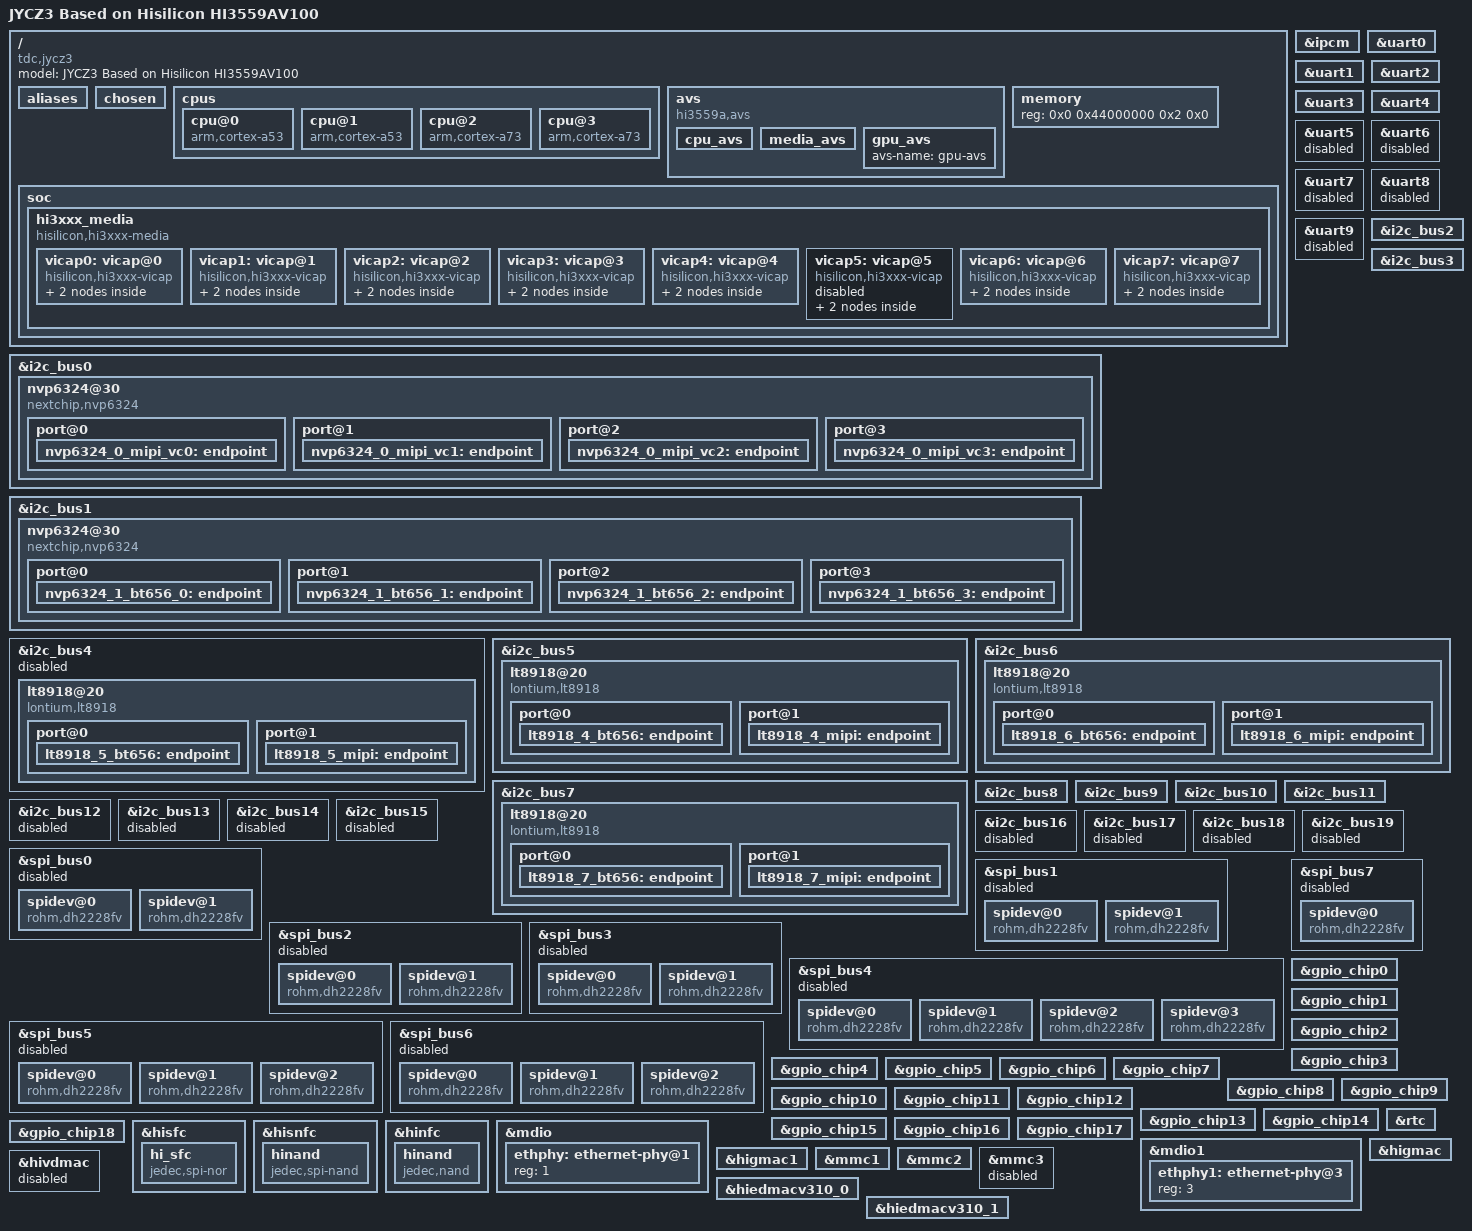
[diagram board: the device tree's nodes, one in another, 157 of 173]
/* Copyright (c) 2017 HiSilicon Technologies Co., Ltd.
 *
 * This program is free software; you can redistribute  it and/or modify it
 * under  the terms of  the GNU General  Public License as published by the
 * Free Software Foundation;  either version 2 of the  License, or (at your
 * option) any later version.
 *
 * This program is distributed in the hope that it will be useful,
 * but WITHOUT ANY WARRANTY; without even the implied warranty of
 * MERCHANTABILITY or FITNESS FOR A PARTICULAR PURPOSE. See the
 * GNU General Public License for more details.
 *
 * You should have received a copy of the GNU General Public License
 * along with this program.  If not, see <http://www.gnu.org/licenses/>.
 *
 */

/dts-v1/;
/* reserved for warmreset */
/* reserved for arm trustedfirmware */
/* Modify this configuration according to the system framework */
/memreserve/ 0x47000000 0x00200000;
#include "hi3559av100.dtsi"

/ {
	model = "JYCZ3 Based on Hisilicon HI3559AV100";
	compatible = "tdc,jycz3", "hisilicon,hi3559av100";

	aliases {
		serial0 = &uart0;
		serial1 = &uart1;
		serial2 = &uart2;
		serial3 = &uart3;
		serial4 = &uart4;
		serial5 = &uart5;
		serial6 = &uart6;
		serial7 = &uart7;
		serial8 = &uart8;
		serial9 = &uart9;

		i2c0 = &i2c_bus0;
		i2c1 = &i2c_bus1;
		i2c2 = &i2c_bus2;
		i2c3 = &i2c_bus3;
		i2c4 = &i2c_bus4;
		i2c5 = &i2c_bus5;
		i2c6 = &i2c_bus6;
		i2c7 = &i2c_bus7;
		i2c8 = &i2c_bus8;
		i2c9 = &i2c_bus9;
		i2c10 = &i2c_bus10;
		i2c11 = &i2c_bus11;
		i2c12 = &i2c_bus12;
		i2c13 = &i2c_bus13;
		i2c14 = &i2c_bus14;
		i2c15 = &i2c_bus15;
		i2c16 = &i2c_bus16;
		i2c17 = &i2c_bus17;
		i2c18 = &i2c_bus18;
		i2c19 = &i2c_bus19;

		spi0 = &spi_bus0;
		spi1 = &spi_bus1;
		spi2 = &spi_bus2;
		spi3 = &spi_bus3;
		spi4 = &spi_bus4;
		spi5 = &spi_bus5;
		spi6 = &spi_bus6;
		spi7 = &spi_bus7;

		gpio0 = &gpio_chip0;
		gpio1 = &gpio_chip1;
		gpio2 = &gpio_chip2;
		gpio3 = &gpio_chip3;
		gpio4 = &gpio_chip4;
		gpio5 = &gpio_chip5;
		gpio6 = &gpio_chip6;
		gpio7 = &gpio_chip7;
		gpio8 = &gpio_chip8;
		gpio9 = &gpio_chip9;
		gpio10 = &gpio_chip10;
		gpio11 = &gpio_chip11;
		gpio12 = &gpio_chip12;
		gpio13 = &gpio_chip13;
		gpio14 = &gpio_chip14;
		gpio15 = &gpio_chip15;
		gpio16 = &gpio_chip16;
		gpio17 = &gpio_chip17;
		gpio18 = &gpio_chip18;
		videv0 = &vicap0;
		videv1 = &vicap1;
		videv2 = &vicap2;
		videv3 = &vicap3;
		videv4 = &vicap4;
		videv5 = &vicap5;
		videv6 = &vicap6;
		videv7 = &vicap7;
	};

	chosen {
		bootargs = "mem=512M console=ttyAMA0,115200 clk_ignore_unused root=/dev/mtdblock2 rootfstype=yaffs2 rw mtdparts=hinand:1M(boot),9M(kernel),32M(rootfs),1M(this_bootargs_string_is_reserved_for_bootargs_form_uboot!!!_it_must_be_longer_than_bootargs_form_uboot!!!_this_bootargs_string_is_reserved_for_bootargs_form_uboot!!!_it_must_be_longer_than_bootargs_form_uboot!!!_this_bootargs_string_is_reserved_for_bootargs_form_uboot!!!_it_must_be_longer_than_bootargs_form_uboot!!!_this_bootargs_string_is_reserved_for_bootargs_form_uboot!!!_it_must_be_longer_than_bootargs_form_uboot!!!_this_bootargs_string_is_reserved_for_bootargs_form_uboot!!!_it_must_be_longer_than_bootargs_form_uboot!!!)";

		linux,initrd-start = <0x60000040>;
		linux,initrd-end = <0x61000000>;
	};

	cpus {
		#address-cells = <2>;
		#size-cells = <0>;

		cpu@0 {
			compatible = "arm,cortex-a53";
			device_type = "cpu";
			reg = <0x0 0x0>;
			enable-method = "psci";
			clock-latency = <100000>; /* From legacy driver */
			cpu-idle-states = <&CPU_POWERDOWN &CPU_STANDBY>;
		};

		cpu@1 {
			compatible = "arm,cortex-a53";
			device_type = "cpu";
			reg = <0x0 0x1>;
			enable-method = "psci";
			clock-latency = <200000>; /* From legacy driver */
			cpu-idle-states = <&CPU_POWERDOWN &CPU_STANDBY>;
		};
		cpu@2 {
			compatible = "arm,cortex-a73";
			device_type = "cpu";
			reg = <0x0 0x100>;
			enable-method = "psci";
			cpu-idle-states = <&CPU_POWERDOWN &CPU_STANDBY>;
			vcc-supply = <&a73_regulator>;
		};
		cpu@3 {
			compatible = "arm,cortex-a73";
			device_type = "cpu";
			reg = <0x0 0x101>;
			enable-method = "psci";
			operating-points = <
				792000 796000
				1296000 888000
				1608000 988000
				>;
			clocks = <&clock HI3559AV100_A73_MUX>,
					<&clock HI3559AV100_FIXED_24M>,
					<&clock HI3559AV100_APLL_CLK>,
					<&clock HI3559AV100_FIXED_1000M>;
			clock-names = "a73_mux","24m","apll","1000m";
			clock-latency = <400000>; /* From legacy driver */
			cpu-idle-states = <&CPU_POWERDOWN &CPU_STANDBY>;
			vcc-supply = <&a73_regulator>;
		};

	};

	avs {
	    compatible = "hi3559a,avs";
	    avs-num = <3>;
	    avs-name-array = "cpu-avs","media-avs","gpu-avs";
	    cpu_avs: cpu_avs{
			avs-name = "cpu-avs";
			opp-num = <6>;
			opp-freq = <1250000 1150000 1000000 930000 792000 594000 >;
			opp-volt-min = <870000 870000 800000 800000 740000 740000>;
			opp-hpm = <310 310 280 280 250 250>;
			opp-div = <24 22 19 18 15 11>;
			opp-volt-max = <1060000>;
			};

	    media_avs: media_avs{
			avs-name = "media-avs";
			opp-num = <4>;
			opp-prof-num = <2>;
			opp-temp-num = <2>;
			opp-temp = <50 200>;
			opp-freq = <1 2 3 4>;
			opp-volt-min = <
				/* profile2    profile3*/
                  770000       770000
                  770000       770000
				  >;
			opp-hpm = <
				/* profile2    profile3*/
				     210       215
				     190       215
				  >;
			opp-div = <3 3 3 3>;
			opp-volt-max = <
				/* profile2    profile3*/
                   977000       977000
                   977000       977000
				>;
			};

		gpu_avs: gpu_avs{
			avs-name = "gpu-avs";
			};

	};
	memory {
		device_type = "memory";
		reg = <0x0 0x44000000 0x2 0x0>; /* system memory base */
	};

	soc {
		hi3xxx_media: hi3xxx_media {
			compatible = "hisilicon,hi3xxx-media", "simple-bus";
			#address-cells = <1>;
			#size-cells = <0>;

			vicap0: vicap@0 {
				compatible = "hisilicon,hi3xxx-vicap";
				status = "disabled";
			};

			vicap1: vicap@1 {
				compatible = "hisilicon,hi3xxx-vicap";
				status = "disabled";
			};

			vicap2: vicap@2 {
				compatible = "hisilicon,hi3xxx-vicap";
				status = "disabled";
			};

			vicap3: vicap@3 {
				compatible = "hisilicon,hi3xxx-vicap";
				status = "disabled";
			};

			vicap4: vicap@4 {
				compatible = "hisilicon,hi3xxx-vicap";
				status = "disabled";
			};

			vicap5: vicap@5 {
				compatible = "hisilicon,hi3xxx-vicap";
				status = "disabled";
			};

			vicap6: vicap@6 {
				compatible = "hisilicon,hi3xxx-vicap";
				status = "disabled";
			};

			vicap7: vicap@7 {
				compatible = "hisilicon,hi3xxx-vicap";
				status = "disabled";
			};
		};
	};
};

&ipcm {
    status = "okay";
};

&uart0 {
	status = "okay";
};

&uart1 {
	status = "okay";
};

&uart2 {
	status = "okay";
};

&uart3 {
	status = "okay";
};

&uart4 {
	status = "okay";
};

&uart5 {
	status = "disabled";
};

&uart6 {
	status = "disabled";
};

&uart7 {
	status = "disabled";
};

&uart8 {
	status = "disabled";
};

&uart9 {
	status = "disabled";
};

&i2c_bus0 {
	status = "okay";

	#address-cells = <1>;
	#size-cells = <0>;
	nvp6324@30 {
		compatible = "nextchip,nvp6324";
		reg = <0x30>;
		reset-gpios = <&gpio_chip5 0 1>;
		nvp,is_mipi;

		#address-cells = <1>;
		#size-cells = <0>;
		port@0 {
			reg = <0>;
			hi3xxx,phy-channel;
			nvp6324_0_mipi_vc0: endpoint {
				remote-endpoint = <&vicap0_mipi>;
				data-lanes = <0 1 2 3>;
			};
		};
		port@1 {
			reg = <1>;
			hi3xxx,virtual-channel;
			nvp6324_0_mipi_vc1: endpoint {
				remote-endpoint = <&vicap1_mipi>;
				data-lanes = <0xff 0xff 0xff 0xff>;
			};
		};
		port@2 {
			reg = <2>;
			hi3xxx,virtual-channel;
			nvp6324_0_mipi_vc2: endpoint {
				remote-endpoint = <&vicap2_mipi>;
				data-lanes = <0xff 0xff 0xff 0xff>;
			};
		};
		port@3 {
			reg = <3>;
			hi3xxx,virtual-channel;
			nvp6324_0_mipi_vc3: endpoint {
				remote-endpoint = <&vicap3_mipi>;
				data-lanes = <0xff 0xff 0xff 0xff>;
			};
		};
	};
};

&i2c_bus1 {
	status = "okay";

	#address-cells = <1>;
	#size-cells = <0>;
	nvp6324@30 {
		compatible = "nextchip,nvp6324";
		reg = <0x30>;
		reset-gpios = <&gpio_chip5 2 1>;

		#address-cells = <1>;
		#size-cells = <0>;
		port@0 {
			reg = <0>;
			hi3xxx,phy-channel;
			nvp6324_1_bt656_0: endpoint {
				remote-endpoint = <&lt8918_4_bt656>;
				data-lanes = <0 1>;
			};
		};
		port@1 {
			reg = <1>;
			hi3xxx,virtual-channel;
			nvp6324_1_bt656_1: endpoint {
				remote-endpoint = <&lt8918_5_bt656>;
				data-lanes = <0 1>;
			};
		};
		port@2 {
			reg = <2>;
			hi3xxx,virtual-channel;
			nvp6324_1_bt656_2: endpoint {
				remote-endpoint = <&lt8918_6_bt656>;
				data-lanes = <0 1>;
			};
		};
		port@3 {
			reg = <3>;
			hi3xxx,virtual-channel;
			nvp6324_1_bt656_3: endpoint {
				remote-endpoint = <&lt8918_7_bt656>;
				data-lanes = <0 1>;
			};
		};
	};
};

&i2c_bus2 {
	status = "okay";
};

&i2c_bus3 {
	status = "okay";
};

&i2c_bus4 {
	status = "disabled";

	#address-cells = <1>;
	#size-cells = <0>;
	lt8918@20 {
		compatible = "lontium,lt8918";
		reg = <0x20>;
		reset-gpios = <&gpio_chip3 2 1>;

		#address-cells = <1>;
		#size-cells = <0>;
		port@0 {
			reg = <0>;
			hi3xxx,uplink;
			lt8918_5_bt656: endpoint {
				remote-endpoint = <&nvp6324_1_bt656_1>;
				data-lanes = <0 0 0 0>;
			};
		};
		port@1 {
			reg = <1>;
			hi3xxx,downlink;
			lt8918_5_mipi: endpoint {
				remote-endpoint = <&vicap5_mipi>;
				data-lanes = <0 1>;
			};
		};
	};
};

&i2c_bus5 {
	status = "okay";

	#address-cells = <1>;
	#size-cells = <0>;
	lt8918@20 {
		compatible = "lontium,lt8918";
		reg = <0x20>;
		reset-gpios = <&gpio_chip3 6 1>;

		#address-cells = <1>;
		#size-cells = <0>;
		port@0 {
			reg = <0>;
			hi3xxx,uplink;
			lt8918_4_bt656: endpoint {
				remote-endpoint = <&nvp6324_1_bt656_0>;
				data-lanes = <0 0 0 0>;
			};
		};
		port@1 {
			reg = <1>;
			hi3xxx,downlink;
			lt8918_4_mipi: endpoint {
				remote-endpoint = <&vicap4_mipi>;
				data-lanes = <0 1 2 3>;
			};
		};
	};
};

&i2c_bus6 {
	status = "okay";

	#address-cells = <1>;
	#size-cells = <0>;
	lt8918@20 {
		compatible = "lontium,lt8918";
		reg = <0x20>;
		reset-gpios = <&gpio_chip4 2 1>;

		#address-cells = <1>;
		#size-cells = <0>;
		port@0 {
			reg = <0>;
			hi3xxx,uplink;
			lt8918_6_bt656: endpoint {
				remote-endpoint = <&nvp6324_1_bt656_2>;
				data-lanes = <0 0 0 0>;
			};
		};
		port@1 {
			reg = <1>;
			hi3xxx,downlink;
			lt8918_6_mipi: endpoint {
				remote-endpoint = <&vicap6_mipi>;
				data-lanes = <0 1>;
			};
		};
	};
};

&i2c_bus7 {
	status = "okay";

	#address-cells = <1>;
	#size-cells = <0>;
	lt8918@20 {
		compatible = "lontium,lt8918";
		reg = <0x20>;
		reset-gpios = <&gpio_chip4 6 1>;

		#address-cells = <1>;
		#size-cells = <0>;
		port@0 {
			reg = <0>;
			hi3xxx,uplink;
			lt8918_7_bt656: endpoint {
				remote-endpoint = <&nvp6324_1_bt656_3>;
				data-lanes = <0 0 0 0>;
			};
		};
		port@1 {
			reg = <1>;
			hi3xxx,downlink;
			lt8918_7_mipi: endpoint {
				remote-endpoint = <&vicap7_mipi>;
				data-lanes = <0 1>;
			};
		};
	};
};

&i2c_bus8 {
	status = "okay";
};

&i2c_bus9 {
	status = "okay";
};

&i2c_bus10 {
	status = "okay";
};

&i2c_bus11 {
	status = "okay";
};

&i2c_bus12 {
	status = "disabled";
};

&i2c_bus13 {
	status = "disabled";
};

&i2c_bus14 {
	status = "disabled";
};

&i2c_bus15 {
	status = "disabled";
};

&i2c_bus16 {
	status = "disabled";
};

&i2c_bus17 {
	status = "disabled";
};

&i2c_bus18 {
	status = "disabled";
};

&i2c_bus19 {
	status = "disabled";
};

&spi_bus0{
	status = "disabled";

	spidev@0 {
		compatible = "rohm,dh2228fv";
		reg = <0>;
		pl022,interface = <0>;
		pl022,com-mode = <0>;
		spi-max-frequency = <24750000>;
	};

	spidev@1 {
		compatible = "rohm,dh2228fv";
		reg = <1>;
		pl022,interface = <0>;
		pl022,com-mode = <0>;
		spi-max-frequency = <24750000>;
	};
};

&spi_bus1{
	status = "disabled";

	spidev@0 {
		compatible = "rohm,dh2228fv";
		reg = <0>;
		pl022,interface = <0>;
		pl022,com-mode = <0>;
		spi-max-frequency = <24750000>;
	};

	spidev@1 {
		compatible = "rohm,dh2228fv";
		reg = <1>;
		pl022,interface = <0>;
		pl022,com-mode = <0>;
		spi-max-frequency = <24750000>;
	};
};

&spi_bus2{
	status = "disabled";

	spidev@0 {
		compatible = "rohm,dh2228fv";
		reg = <0>;
		pl022,interface = <0>;
		pl022,com-mode = <0>;
		spi-max-frequency = <24750000>;
	};

	spidev@1 {
		compatible = "rohm,dh2228fv";
		reg = <1>;
		pl022,interface = <0>;
		pl022,com-mode = <0>;
		spi-max-frequency = <24750000>;
	};
};

&spi_bus3{
	status = "disabled";

	spidev@0 {
		compatible = "rohm,dh2228fv";
		reg = <0>;
		pl022,interface = <0>;
		pl022,com-mode = <0>;
		spi-max-frequency = <24750000>;
	};

	spidev@1 {
		compatible = "rohm,dh2228fv";
		reg = <1>;
		pl022,interface = <0>;
		pl022,com-mode = <0>;
		spi-max-frequency = <24750000>;
	};
};

&spi_bus4{
	status = "disabled";

	spidev@0 {
		compatible = "rohm,dh2228fv";
		reg = <0>;
		pl022,interface = <0>;
		pl022,com-mode = <0>;
		spi-max-frequency = <24750000>;
	};

	spidev@1 {
		compatible = "rohm,dh2228fv";
		reg = <1>;
		pl022,interface = <0>;
		pl022,com-mode = <0>;
		spi-max-frequency = <24750000>;
	};

	spidev@2 {
		compatible = "rohm,dh2228fv";
		reg = <2>;
		pl022,interface = <0>;
		pl022,com-mode = <0>;
		spi-max-frequency = <24750000>;
	};

	spidev@3 {
		compatible = "rohm,dh2228fv";
		reg = <3>;
		pl022,interface = <0>;
		pl022,com-mode = <0>;
		spi-max-frequency = <24750000>;
	};
};

&spi_bus5{
	status = "disabled";

	spidev@0 {
		compatible = "rohm,dh2228fv";
		reg = <0>;
		pl022,interface = <0>;
		pl022,com-mode = <0>;
		spi-max-frequency = <48000000>;
	};

	spidev@1 {
		compatible = "rohm,dh2228fv";
		reg = <1>;
		pl022,interface = <0>;
		pl022,com-mode = <0>;
		spi-max-frequency = <48000000>;
	};
	spidev@2 {
		compatible = "rohm,dh2228fv";
		reg = <2>;
		pl022,interface = <0>;
		pl022,com-mode = <0>;
		spi-max-frequency = <48000000>;
	};
};

&spi_bus6{
	status = "disabled";

	spidev@0 {
		compatible = "rohm,dh2228fv";
		reg = <0>;
		pl022,interface = <0>;
		pl022,com-mode = <0>;
		spi-max-frequency = <48000000>;
	};

	spidev@1 {
		compatible = "rohm,dh2228fv";
		reg = <1>;
		pl022,interface = <0>;
		pl022,com-mode = <0>;
		spi-max-frequency = <48000000>;
	};
	spidev@2 {
		compatible = "rohm,dh2228fv";
		reg = <2>;
		pl022,interface = <0>;
		pl022,com-mode = <0>;
		spi-max-frequency = <48000000>;
	};
};

&spi_bus7{
	status = "disabled";

	spidev@0 {
		compatible = "rohm,dh2228fv";
		reg = <0>;
		pl022,interface = <0>;
		pl022,com-mode = <0>;
		spi-max-frequency = <48000000>;
	};
};

&gpio_chip0 {
	status = "okay";
};

&gpio_chip1 {
	status = "okay";
};

&gpio_chip2 {
	status = "okay";
};

&gpio_chip3 {
	status = "okay";
};

&gpio_chip4 {
	status = "okay";
};

&gpio_chip5 {
	status = "okay";
};

&gpio_chip6 {
	status = "okay";
};

&gpio_chip7 {
	status = "okay";
};

&gpio_chip8 {
	status = "okay";
};

&gpio_chip9 {
	status = "okay";
};

&gpio_chip10 {
	status = "okay";
};

&gpio_chip11 {
	status = "okay";
};

&gpio_chip12 {
	status = "okay";
};

&gpio_chip13 {
	status = "okay";
};

&gpio_chip14 {
	status = "okay";
};

&gpio_chip15 {
	status = "okay";
};

&gpio_chip16 {
	status = "okay";
};

&gpio_chip17 {
	status = "okay";
};

&gpio_chip18 {
	status = "okay";
};

&rtc{
	status = "okay";
};

&hisfc {
	hi_sfc {
		compatible = "jedec,spi-nor";
		reg = <0>;
		spi-max-frequency = <160000000>;
		m25p,fast-read;
	};
};

&hisnfc {
	hinand {
		compatible = "jedec,spi-nand";
		reg = <0>;
		spi-max-frequency = <160000000>;
	};
};

&hinfc {
	hinand {
		compatible = "jedec,nand";
		reg = <0>;
		nand-max-frequency = <200000000>;
	};
};

&mdio {
	ethphy: ethernet-phy@1 {
		reg = <1>;
	};
};

&mdio1 {
	ethphy1: ethernet-phy@3 {
		reg = <3>;
	};
};

&higmac {
	phy-handle = <&ethphy>;
	phy-mode = "rgmii";
};

&higmac1 {
	phy-handle = <&ethphy1>;
	phy-mode = "rgmii";
};

&mmc1 {
	status = "okay";
};

&mmc2 {
	status = "okay";
};

&mmc3 {
	status = "disabled";
};

&hivdmac {
	status = "disabled";
};

&hiedmacv310_0 {
	status = "okay";
};

&hiedmacv310_1 {
	status = "okay";
};

&vicap0 {
	status = "okay";

	#address-cells = <1>;
	#size-cells = <0>;
	port@0 {
		reg = <0>;
		hi3xxx,phy-channel;
		vicap0_mipi: endpoint {
			remote-endpoint = <&nvp6324_0_mipi_vc0>;
			data-lanes = <1 2 3 4>;
		};
	};
};

&vicap1 {
	status = "okay";

	#address-cells = <1>;
	#size-cells = <0>;
	port@0 {
		reg = <0>;
		hi3xxx,virtual-channel;
		vicap1_mipi: endpoint {
			remote-endpoint = <&nvp6324_0_mipi_vc1>;
			data-lanes = <0xff 0xff 0xff 0xff>;
		};
	};
};

&vicap2 {
	status = "okay";

	#address-cells = <1>;
	#size-cells = <0>;
	port@0 {
		reg = <0>;
		hi3xxx,virtual-channel;
		vicap2_mipi: endpoint {
			remote-endpoint = <&nvp6324_0_mipi_vc2>;
			data-lanes = <0xff 0xff 0xff 0xff>;
		};
	};
};

&vicap3 {
	status = "okay";

	#address-cells = <1>;
	#size-cells = <0>;
	port@0 {
		reg = <0>;
		hi3xxx,virtual-channel;
		vicap3_mipi: endpoint {
			remote-endpoint = <&nvp6324_0_mipi_vc3>;
			data-lanes = <0xff 0xff 0xff 0xff>;
		};
	};
};

&vicap4 {
	status = "okay";

	#address-cells = <1>;
	#size-cells = <0>;
	port@0 {
		reg = <0>;
		vicap4_mipi: endpoint {
			remote-endpoint = <&lt8918_4_mipi>;
			data-lanes = <8 9 10 11>;
		};
	};
};

&vicap5 {
	status = "disabled";

	#address-cells = <1>;
	#size-cells = <0>;
	port@0 {
		reg = <0>;
		vicap5_mipi: endpoint {
			remote-endpoint = <&lt8918_5_mipi>;
			data-lanes = <9 11>;
		};
	};
};

&vicap6 {
	status = "okay";

	#address-cells = <1>;
	#size-cells = <0>;
	port@0 {
		reg = <0>;
		vicap6_mipi: endpoint {
			remote-endpoint = <&lt8918_6_mipi>;
			data-lanes = <12 14>;
		};
	};
};

&vicap7 {
	status = "okay";

	#address-cells = <1>;
	#size-cells = <0>;
	port@0 {
		reg = <0>;
		vicap7_mipi: endpoint {
			remote-endpoint = <&lt8918_7_mipi>;
			data-lanes = <13 15>;
		};
	};
};
